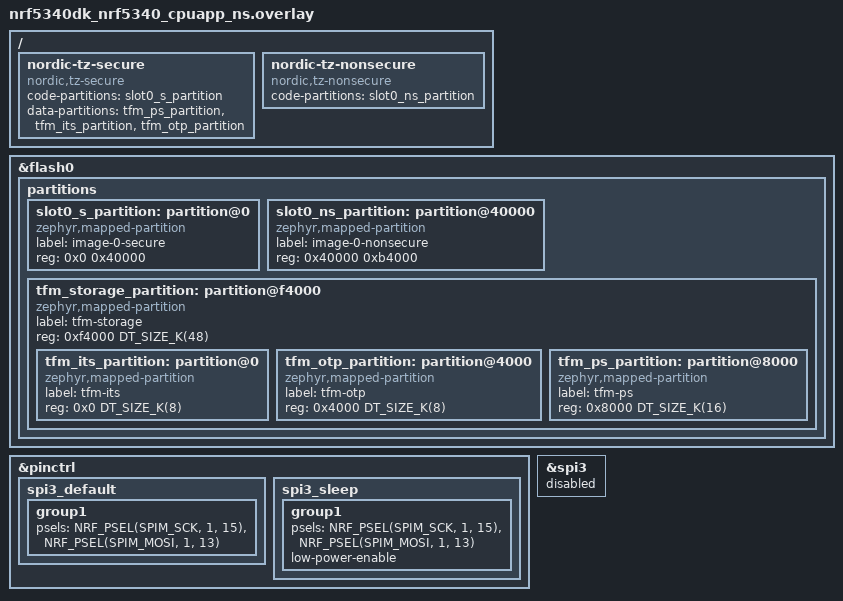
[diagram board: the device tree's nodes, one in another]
/* Copyright (c) 2022 Nordic Semiconductor ASA
 *
 * SPDX-License-Identifier: LicenseRef-Nordic-5-Clause
 */

/delete-node/ &boot_partition;
/delete-node/ &slot0_partition;
/delete-node/ &slot1_partition;
/delete-node/ &storage_partition;

/delete-node/ &tfm_its_partition;
/delete-node/ &tfm_otp_partition;
/delete-node/ &tfm_ps_partition;

&flash0 {
	partitions {
		slot0_s_partition: partition@0 {
			compatible = "zephyr,mapped-partition";
			label = "image-0-secure";
			reg = <0x0 0x40000>;
		};

		slot0_ns_partition: partition@40000 {
			compatible = "zephyr,mapped-partition";
			label = "image-0-nonsecure";
			reg = <0x40000 0xb4000>;
		};

		tfm_storage_partition: partition@f4000 {
			compatible = "zephyr,mapped-partition";
			label = "tfm-storage";
			reg = <0xf4000 DT_SIZE_K(48)>;
			ranges = <0x0 0xf4000 DT_SIZE_K(48)>;
			#address-cells = <1>;
			#size-cells = <1>;

			tfm_its_partition: partition@0 {
				compatible = "zephyr,mapped-partition";
				label = "tfm-its";
				reg = <0x0 DT_SIZE_K(8)>;
			};

			tfm_otp_partition: partition@4000 {
				compatible = "zephyr,mapped-partition";
				label = "tfm-otp";
				reg = <0x4000 DT_SIZE_K(8)>;
			};

			tfm_ps_partition: partition@8000 {
				compatible = "zephyr,mapped-partition";
				label = "tfm-ps";
				reg = <0x8000 DT_SIZE_K(16)>;
			};
		};
	};
};

&pinctrl {
	spi3_default: spi3_default {
		group1 {
			psels = <NRF_PSEL(SPIM_SCK, 1, 15)>,
				<NRF_PSEL(SPIM_MOSI, 1, 13)>;
		};
	};

	spi3_sleep: spi3_sleep {
		group1 {
			psels = <NRF_PSEL(SPIM_SCK, 1, 15)>,
				<NRF_PSEL(SPIM_MOSI, 1, 13)>;
			low-power-enable;
		};
	};
};

&spi3 {
	/* Disabled in non-secure image. */
	status = "disabled";
};

/ {
	/delete-node/ nordic-tz-secure;
	/delete-node/ nordic-tz-nonsecure;

	nordic-tz-secure {
		compatible = "nordic,tz-secure";
		code-partitions = <&slot0_s_partition>;
		data-partitions = <&tfm_ps_partition>,
				  <&tfm_its_partition>,
				  <&tfm_otp_partition>;
	};

	nordic-tz-nonsecure {
		compatible = "nordic,tz-nonsecure";
		code-partitions = <&slot0_ns_partition>;
	};
};
